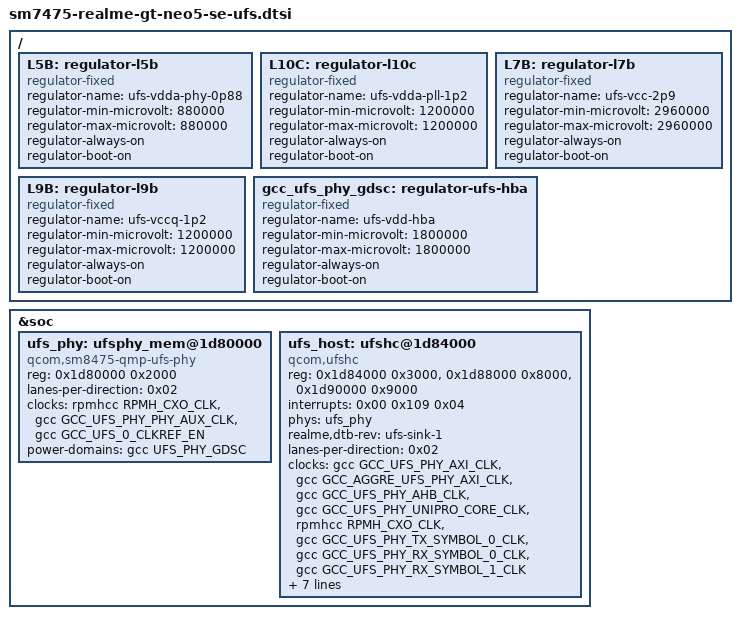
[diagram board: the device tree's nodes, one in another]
// SPDX-License-Identifier: (GPL-2.0-only OR BSD-2-Clause)
/*
 * UFS host and QMP PHY for the SM7475 board tree.
 *
 * Both nodes exist in the stock base (vendor_boot slot msm-id 0x24f), and
 * tools/boot/gen-soc-spmi.py used to migrate them verbatim, but the copy it
 * produced could not work:
 *
 *  - the PHY came through without a `compatible` at all, so no driver ever
 *    bound to it and the host sat in
 *    "deferred probe pending: platform: wait for supplier" forever;
 *  - the generator rewrites only the first cell of each <...> group back to a
 *    label, so the stock `clocks` property - whose phandle values are
 *    interleaved with the clock ids - lost every phandle after the first one.
 *
 * The register blocks, the clock and reset ids, and the interrupt are taken
 * from the stock base; the clock references are written with this tree's
 * labels and the dt-bindings macros, and the properties the mainline bindings
 * require (compatible, power-domains) are added.  The stock properties only
 * the downstream driver reads (qcom,ufs-bus-bw,*, qcom,prime-mask,
 * qcom,silver-mask, multi-level-clk-scaling-support, disable-cgc, the
 * axi/ice/unipro turbo frequencies, qcom,iommu-dma, dev-ref-clk-freq and the
 * per-priority qos0/qos1 children) are dropped.
 *
 * The PHY sits at 0x1d80000 with a 2 KiB window, which is the SM8475 ("cape",
 * the SoC this device's GCC is derived from) layout; the SM8450 layout puts
 * its PCS at 0xc00 inside a 4 KiB window instead.
 *
 * The rails the factory dtbo wires into these two nodes are modelled at the
 * bottom of the file, and the two nodes deliberately do not carry the stock
 * `ufshc_mem` / `ufsphy_mem` labels - both points are explained there.
 */

/*
 * These two nodes carry the private labels ufs_host / ufs_phy, NOT the stock
 * `ufshc_mem` / `ufsphy_mem`.
 *
 * The factory dtbo has fragment@18 targeting `ufsphy_mem` and fragment@19
 * targeting `ufshc_mem`, and the bootloader merges both into whatever node
 * holds those labels.  Measured on the device, that merge overwrites the
 * node's properties: our PHY's `compatible` came back from
 * /sys/firmware/devicetree/base as the downstream string
 *
 *   qcom,ufs-phy-qmp-v4-cape
 *
 * which no mainline driver matches, so the PHY could never bind - and the
 * fragments' supplies point at labels that have no driver either.  Keeping
 * the stock labels on empty sink nodes (sm7475-realme-gt-neo5-se-abl-
 * labels.dtsi) makes the vendor content land there instead, which leaves our
 * nodes - and therefore the drivers - intact.
 *
 * The factory dtbo (all three of its dt_table entries) carries
 *
 *   fragment@18 -> ufsphy_mem:  vdda-phy-supply = <&L5B>,
 *                               vdda-pll-supply = <&L10C>
 *   fragment@19 -> ufshc_mem:   vdd-hba-supply = <&gcc_ufs_phy_gdsc>,
 *                               vcc-supply = <&L7B>,
 *                               vccq-supply = <&L9B>,
 *                               qcom,vddp-ref-clk-supply = <&L9B>
 *
 * and the bootloader merges those fragments into our nodes.  It only adds the
 * properties our nodes lack (which is why the `compatible` above survives the
 * merge), so both nodes end up asking for supplies.
 *
 * None of those five labels had a real node in this tree - they were only sink
 * entries in sm7475-realme-gt-neo5-se-abl-labels.dtsi - and a supply that
 * resolves to a node with no driver never becomes a regulator device, so the
 * consumer defers forever:
 *
 *   deferred probe pending: platform: wait for supplier /abl_overlay_sink/abl-sym-15
 *
 * That is what kept `1d80000.ufsphy_mem` and `1d84000.ufshc` unbound.
 *
 * The PMIC regulators (and the GCC GDSC, which the stock tree passes as
 * vdd-hba) are not described yet, but the bootloader leaves these rails
 * powered - it boots from UFS after all - so a fixed always-on regulator is
 * both honest and sufficient: the drivers only enable the supply and read the
 * max-microamp values the fragment also carries.
 */
/ {
	L5B: regulator-l5b {
		compatible = "regulator-fixed";
		regulator-name = "ufs-vdda-phy-0p88";
		regulator-min-microvolt = <880000>;
		regulator-max-microvolt = <880000>;
		regulator-always-on;
		regulator-boot-on;
	};

	L10C: regulator-l10c {
		compatible = "regulator-fixed";
		regulator-name = "ufs-vdda-pll-1p2";
		regulator-min-microvolt = <1200000>;
		regulator-max-microvolt = <1200000>;
		regulator-always-on;
		regulator-boot-on;
	};

	L7B: regulator-l7b {
		compatible = "regulator-fixed";
		regulator-name = "ufs-vcc-2p9";
		regulator-min-microvolt = <2960000>;
		regulator-max-microvolt = <2960000>;
		regulator-always-on;
		regulator-boot-on;
	};

	L9B: regulator-l9b {
		compatible = "regulator-fixed";
		regulator-name = "ufs-vccq-1p2";
		regulator-min-microvolt = <1200000>;
		regulator-max-microvolt = <1200000>;
		regulator-always-on;
		regulator-boot-on;
	};

	/* Only has to resolve: mainline drives the UFS GDSC through the host's
	 * power-domains, this node is what the stock tree passes as vdd-hba. */
	gcc_ufs_phy_gdsc: regulator-ufs-hba {
		compatible = "regulator-fixed";
		regulator-name = "ufs-vdd-hba";
		regulator-min-microvolt = <1800000>;
		regulator-max-microvolt = <1800000>;
		regulator-always-on;
		regulator-boot-on;
	};
};

&soc {
	ufs_phy: ufsphy_mem@1d80000 {
		compatible = "qcom,sm8475-qmp-ufs-phy";
		reg = <0x1d80000 0x2000>;
		reg-names = "phy_mem";
		#phy-cells = <0x00>;
		#clock-cells = <0x01>;
		lanes-per-direction = <0x02>;
		clocks = <&rpmhcc RPMH_CXO_CLK>,
			 <&gcc GCC_UFS_PHY_PHY_AUX_CLK>,
			 <&gcc GCC_UFS_0_CLKREF_EN>;
		clock-names = "ref", "ref_aux", "qref";
		power-domains = <&gcc UFS_PHY_GDSC>;
		/* No `resets`: the stock node points it at the host and
		 * qmp_ufs_phy_init() only fetches that reset when the config sets
		 * .no_pcs_sw_reset, which sm8475's does not.  Keeping it would only
		 * add a device link back to the host - and since the host already
		 * waits for this PHY (phys = <&ufs_phy>) the two links form an
		 * fw_devlink cycle that leaves both devices unbound
		 * ("deferred probe pending: wait for supplier").
		 */
		status = "okay";
	};

	ufs_host: ufshc@1d84000 {
		compatible = "qcom,ufshc", "jedec,ufs-2.0";
		reg = <0x1d84000 0x3000>, <0x1d88000 0x8000>,
		      <0x1d90000 0x9000>;
		reg-names = "ufs_mem", "ufs_ice", "ufs_ice_hwkm";
		interrupts = <0x00 0x109 0x04>;
		phys = <&ufs_phy>;
		phy-names = "ufsphy";
		/* Shows up in /sys/firmware/devicetree/base, so the initramfs
		 * diagnostics can tell which image is actually booted. */
		realme,dtb-rev = "ufs-sink-1";
		#reset-cells = <0x01>;
		lanes-per-direction = <0x02>;
		clocks = <&gcc GCC_UFS_PHY_AXI_CLK>,
			 <&gcc GCC_AGGRE_UFS_PHY_AXI_CLK>,
			 <&gcc GCC_UFS_PHY_AHB_CLK>,
			 <&gcc GCC_UFS_PHY_UNIPRO_CORE_CLK>,
			 <&rpmhcc RPMH_CXO_CLK>,
			 <&gcc GCC_UFS_PHY_TX_SYMBOL_0_CLK>,
			 <&gcc GCC_UFS_PHY_RX_SYMBOL_0_CLK>,
			 <&gcc GCC_UFS_PHY_RX_SYMBOL_1_CLK>;
		clock-names = "core_clk", "bus_aggr_clk", "iface_clk",
			      "core_clk_unipro", "ref_clk", "tx_lane0_sync_clk",
			      "rx_lane0_sync_clk", "rx_lane1_sync_clk";
		freq-table-hz = <75000000 300000000>, <0 0>, <0 0>,
				<75000000 300000000>, <75000000 300000000>,
				<0 0>, <0 0>, <0 0>;
		power-domains = <&gcc UFS_PHY_GDSC>;
		resets = <&gcc GCC_UFS_PHY_BCR>;
		reset-names = "rst";
		iommus = <&mainline_apps_smmu 0xe0 0x0>;
		dma-coherent;
		status = "okay";
	};
};
